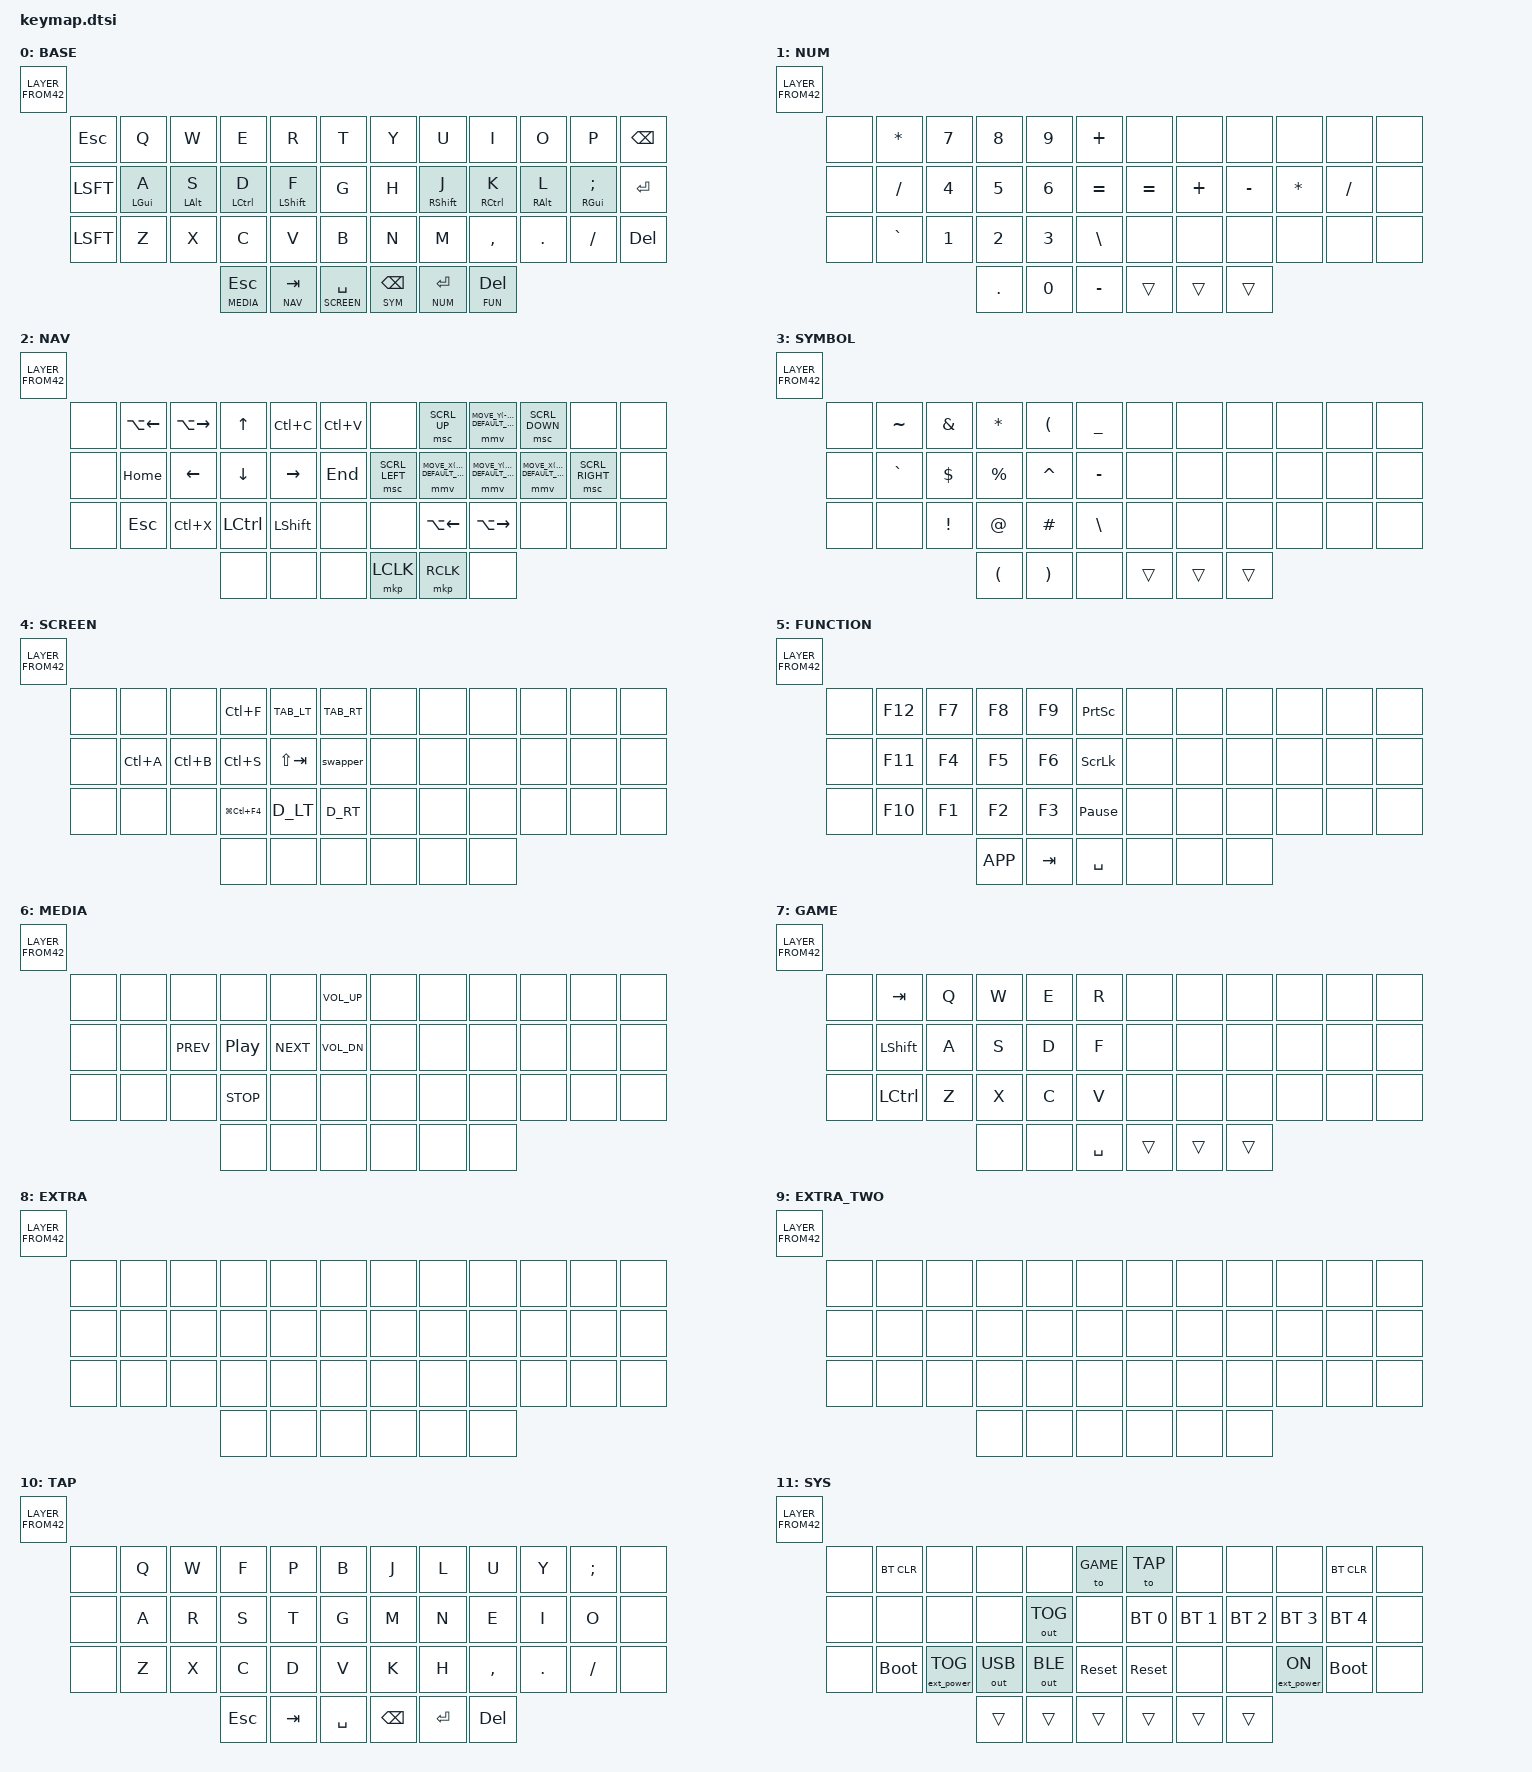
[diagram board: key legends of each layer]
 /*
 * Copyright (c) 2020 The ZMK Contributors
 *
 * SPDX-License-Identifier: MIT
 */

#include <behaviors.dtsi>
#include "zmk-helpers/helper.h"
#include <dt-bindings/zmk/keys.h>
#include <dt-bindings/zmk/bt.h>
#include <dt-bindings/zmk/outputs.h>
#include <dt-bindings/zmk/ext_power.h>

#include "mouse.dtsi"


#include <dt-bindings/zmk/bt.h>

// #define _BT_SEL_KEYS_ &bt BT_SEL 0 &bt BT_SEL 1 &bt BT_SEL 2 &bt BT_SEL 3


#define DEF 0
#define NUM 1
#define NAV 2
#define SYM 3
#define SCREEN 4
#define FUN 5
#define MEDIA 6
#define GAME 7
#define EXTRA 8
#define EXTRA_TWO 9
#define TAP 10
#define SYS 11




// Desktop and tab navigation shortcuts
#define D_LT   LC(LG(LEFT))
#define D_RT   LC(LG(RIGHT))
#define D_CL   LC(LG(F4))


#define TAB_RT LC(TAB)
#define TAB_LT LC(LS(TAB))

// Extra key bindings
#define SWP_POS 16

&lt { quick_tap_ms = <250>; };


#define QUICK_TAP_MS 175
#define TAPPING_TERM_MS 175

/* Timeless homerow mods */

// https://github.com/urob/zmk-config/tree/main#timeless-homerow-mods
#define KEYS_L LT0 LT1 LT2 LT3 LT4 LT5 LM0 LM1 LM2 LM3 LM4 LM5 LB0 LB1 LB2 LB3 LB4 LB5  // left hand
#define KEYS_R RT0 RT1 RT2 RT3 RT4 RT5 RM0 RM1 RM2 RM3 RM4 RM5 RB0 RB1 RB2 RB3 RB4 RB5 // right hand
#define THUMBS LH2 LH1 LH0 RH0 RH1 RH2                                                  // thumbs

ZMK_HOLD_TAP(hml,
    flavor = "balanced";
    tapping-term-ms = <TAPPING_TERM_MS>;
    quick-tap-ms = <QUICK_TAP_MS>;
    require-prior-idle-ms = <150>;
    hold-trigger-key-positions = <KEYS_R THUMBS>;
    hold-trigger-on-release;
    bindings = <&kp>, <&kp>;
)

ZMK_HOLD_TAP(hmr,
    flavor = "balanced";
    tapping-term-ms = <TAPPING_TERM_MS>;
    quick-tap-ms = <QUICK_TAP_MS>;
    require-prior-idle-ms = <150>;
    hold-trigger-key-positions = <KEYS_L THUMBS>;
    hold-trigger-on-release;
    bindings = <&kp>, <&kp>;
)

#define QUICK_TAP_MS 175
/* Homerow mods */

/ {
    behaviors {
        bhm: balanced_homerow_mods {
            compatible = "zmk,behavior-hold-tap";
            #binding-cells = <2>;
            tapping-term-ms = <200>;    // <---[[moderate duration]]
            quick-tap-ms = <0>;
            flavor = "balanced";
            bindings = <&kp>, <&kp>;
        };
        // Swapper for smart alt+tab
        swapper: swapper {
            compatible = "zmk,behavior-tri-state";
            #binding-cells = <0>;
            bindings = <&kt LALT>, <&kp TAB>, <&kt LALT>;
            ignored-key-positions = <SWP_POS>;
        };
        swappermac: swappermac {
            compatible = "zmk,behavior-tri-state";
            #binding-cells = <0>;
            bindings = <&kt LGUI>, <&kp TAB>, <&kt LGUI>;
            ignored-key-positions = <SWP_POS>;
        };
    };
};
/ {
    conditional_layers {
        compatible = "zmk,conditional-layers";
        tri_layer {
            if-layers = <5 6>;
            then-layer = <14>;
        };
    };
};

/ {
    conditional_layers1 {
        compatible = "zmk,conditional-layers";
        tri_layer {
            if-layers = <5 7>;
            then-layer = <14>;
        };
    };
};

/ {
    macros {
        numdot: numdot {
            label = "ZM_numdot";
            compatible = "zmk,behavior-macro";
            #binding-cells = <0>;
            wait-ms = <40>;
            tap-ms = <40>;
            bindings
                = <&macro_press   &kp LALT>    
                , <&macro_tap     &kp KP_N4 &kp KP_N6>    
                , <&macro_release &kp LALT>
                ;
        };
        grtsgn: grtsgn {
            label = "ZM_grtsgn";
            compatible = "zmk,behavior-macro";
            #binding-cells = <0>;
            wait-ms = <40>;
            tap-ms = <40>;
            bindings
                = <&macro_press   &kp LALT>    
                , <&macro_tap     &kp KP_N6 &kp KP_N2>    
                , <&macro_release &kp LALT>
                ;
        };
    };
};

#include "combos.dtsi"

/ {
    keymap {
        compatible = "zmk,keymap";

         default_layer {
            label = "BASE"; // DEFAULT
            bindings = <LAYER_FROM42(
                &kp ESC,      &kp Q,        &kp W,        &kp E,         &kp R,        &kp T,              &kp Y,         &kp U,         &kp I,        &kp O,        &kp P,           &kp BSPC,
                &kp LSFT,     &hml LGUI A,  &hml LALT S,  &hml LCTRL D,  &hml LSHFT F, &kp G,              &kp H,         &hmr RSHFT J,  &hmr RCTRL K, &hmr RALT L,  &hmr RGUI SEMI,  &kp RET,
                &kp LSFT,     &kp Z,        &kp X,        &kp C,         &kp V,        &kp B,              &kp N,         &kp M,         &kp COMMA,    &kp DOT,      &kp FSLH,        &kp DEL,
                                                          &lt MEDIA ESC, &lt NAV TAB,  &lt SCREEN SPACE,   &lt SYM BSPC,  &lt NUM RET,  &lt FUN DEL
            )>;
        };

        num_layer {
            label = "NUM"; // NUM
            bindings = <LAYER_FROM42(
                &none,        &kp ASTRK,    &kp N7,       &kp N8,      &kp N9,       &kp PLUS,     &none,        &none,        &none,       &none,       &none,       &none,
                &none,        &kp SLASH,    &kp N4,       &kp N5,      &kp N6,       &kp EQUAL,    &kp EQUAL,    &kp PLUS,     &kp MINUS,   &kp ASTRK,   &kp SLASH,   &none,
                &none,        &kp GRAVE,    &kp N1,       &kp N2,      &kp N3,       &kp BSLH,     &none,        &none,        &none,       &none,       &none,       &none,
                                                        &kp DOT, &kp N0, &kp MINUS, &trans, &trans, &trans
            )>;
        };

        nav_layer {
            label = "NAV"; // NAV
            bindings = <LAYER_FROM42(
                &none,        &kp LA(LEFT), &kp LA(RIGHT), &kp UP,     &kp LC(C),    &kp LC(V),     &none,           &msc SCRL_UP,                                &mmv MOVE_Y(-ZMK_POINTING_DEFAULT_MOVE_VAL),    &msc SCRL_DOWN,                             &none,           &none,
                &none,        &kp HOME,     &kp LEFT,      &kp DOWN,   &kp RIGHT,    &kp END,       &msc SCRL_LEFT,  &mmv MOVE_X(-ZMK_POINTING_DEFAULT_MOVE_VAL), &mmv MOVE_Y(ZMK_POINTING_DEFAULT_MOVE_VAL),     &mmv MOVE_X(ZMK_POINTING_DEFAULT_MOVE_VAL), &msc SCRL_RIGHT, &none,
                &none,        &kp ESC,      &kp LC(X),     &kp LCTRL,  &kp LSHFT,    &none,         &none,           &kp LA(LEFT),                                &kp LA(RIGHT),                                  &none,                                      &none,           &none,
                                                           &none,      &none,        &none,         &mkp LCLK,       &mkp RCLK,                                   &none
            )>;
        };

        sym_layer {
            label = "SYMBOL"; // SYM
            bindings = <LAYER_FROM42(
                &none,        &kp TILDE,    &kp AMPS,     &kp ASTRK,   &kp LPAR,     &kp UNDER,      &none,        &none,        &none,       &none,       &none,       &none,
                &none,        &kp GRAVE,    &kp DLLR,     &kp PRCNT,   &kp CARET,    &kp MINUS,      &none,        &none,        &none,       &none,       &none,       &none,
                &none,        &none,        &kp EXCL,     &kp AT,      &kp HASH,     &kp BSLH,       &none,        &none,        &none,       &none,       &none,       &none,
                                                          &kp LPAR,    &kp RPAR,     &none,          &trans,       &trans,       &trans
            )>;
        };

        screen_layer {
            label = "SCREEN"; // SCREEN
            bindings = <LAYER_FROM42(
                &none,        &none,        &none,        &kp LC(F),         &kp TAB_LT,    &kp TAB_RT,      &none,        &none,        &none,       &none,       &none,       &none,
                &none,        &kp LC(A),    &kp LC(B),    &kp LC(S),         &kp LS(TAB),   &swapper,        &none,        &none,        &none,       &none,       &none,       &none,
                &none,        &none,        &none,        &kp LG(LC(F4)),    &kp D_LT,      &kp D_RT,        &none,        &none,        &none,       &none,       &none,       &none,
                                                          &none,             &none,         &none,           &none,        &none,        &none
            )>;
        };


        fun_layer {
            label = "FUNCTION"; // FUN
            bindings = <LAYER_FROM42(
                &none,        &kp F12,        &kp F7,       &kp F8,        &kp F9,        &kp PSCRN,            &none,        &none,        &none,       &none,       &none,       &none,
                &none,        &kp F11,        &kp F4,       &kp F5,        &kp F6,        &kp SLCK,             &none,        &none,        &none,       &none,       &none,       &none,
                &none,        &kp F10,        &kp F1,       &kp F2,        &kp F3,        &kp PAUSE_BREAK,      &none,        &none,        &none,       &none,       &none,       &none,
                                                            &kp K_APP,     &kp TAB,       &kp SPACE,            &none,        &none,        &none
            )>;
        };

        media_layer {
            label = "MEDIA"; // MEDIA
            bindings = <LAYER_FROM42(
                &none,        &none,          &none,        &none,        &none,        &kp C_VOL_UP,    &none,        &none,        &none,       &none,       &none,       &none,
                &none,        &none,          &kp C_PREV,   &kp C_PP,     &kp C_NEXT,   &kp C_VOL_DN,    &none,        &none,        &none,       &none,       &none,       &none,
                &none,        &none,          &none,        &kp C_STOP,   &none,        &none,           &none,        &none,        &none,       &none,       &none,       &none,
                                                            &none,        &none,        &none,           &none,        &none,        &none
            )>;
        };

        game_layer {
            label = "GAME"; // VAL
            bindings = <LAYER_FROM42(
                &none,        &kp TAB,      &kp Q,        &kp W,       &kp E,        &kp R,            &none,        &none,        &none,       &none,       &none,       &none,
                &none,        &kp LSHFT,    &kp A,        &kp S,       &kp D,        &kp F,            &none,        &none,        &none,       &none,       &none,       &none,
                &none,        &kp LCTRL,    &kp Z,        &kp X,       &kp C,        &kp V,            &none,        &none,        &none,       &none,       &none,       &none,
                                                          &none,       &none,        &kp SPACE,        &trans,       &trans,       &trans
            )>;
        };

        extra_two_layer {
            label = "EXTRA"; // EXTRA
            bindings = <LAYER_FROM42(
                &none,        &none,        &none,        &none,       &none,        &none,            &none,        &none,        &none,      &none,       &none,       &none,
                &none,        &none,        &none,        &none,       &none,        &none,            &none,        &none,        &none,      &none,       &none,       &none,
                &none,        &none,        &none,        &none,       &none,        &none,            &none,        &none,        &none,      &none,       &none,       &none,
                                                          &none,       &none,        &none,            &none,        &none,        &none
            )>;
        };

         extra_layer {
            label = "EXTRA_TWO"; // EXTRA
            bindings = <LAYER_FROM42(
                &none,        &none,        &none,        &none,       &none,        &none,            &none,        &none,        &none,      &none,       &none,       &none,
                &none,        &none,        &none,        &none,       &none,        &none,            &none,        &none,        &none,      &none,       &none,       &none,
                &none,        &none,        &none,        &none,       &none,        &none,            &none,        &none,        &none,      &none,       &none,       &none,
                                                          &none,       &none,        &none,            &none,        &none,        &none
            )>;
        };

        tap_layer {
            label = "TAP"; // TAP
            bindings = <LAYER_FROM42(
                &none,        &kp Q,        &kp W,        &kp F,       &kp P,        &kp B,            &kp J,        &kp L,        &kp U,       &kp Y,       &kp SEMI,    &none,
                &none,        &kp A,        &kp R,        &kp S,       &kp T,        &kp G,            &kp M,        &kp N,        &kp E,       &kp I,       &kp O,       &none,
                &none,        &kp Z,        &kp X,        &kp C,       &kp D,        &kp V,            &kp K,        &kp H,        &kp COMMA,   &kp DOT,     &kp FSLH,    &none,
                                                          &kp ESC,     &kp TAB,      &kp SPACE,        &kp BSPC,     &kp RET,      &kp DEL
            )>;
        };

        sys_layer {
            label = "SYS"; // SYS
            bindings = <LAYER_FROM42(
                &none,    &bt BT_CLR,    &none,                &none,           &none,           &to GAME,       &to TAP,         &none,           &none,           &none,               &bt BT_CLR,      &none,
                &none,    &none,         &none,                &none,           &out OUT_TOG,    &none,          &bt BT_SEL 0,    &bt BT_SEL 1,    &bt BT_SEL 2,    &bt BT_SEL 3,        &bt BT_SEL 4,    &none,
                &none,    &bootloader,   &ext_power EP_TOG,    &out OUT_USB,    &out OUT_BLE,    &sys_reset,     &sys_reset,      &none,           &none,           &ext_power EP_ON,    &bootloader,     &none,
                                                               &trans,          &trans,          &trans,         &trans,          &trans,          &trans
            )>;
        };
    };
};
